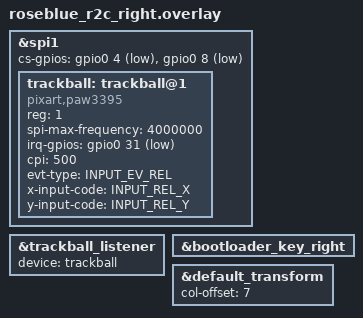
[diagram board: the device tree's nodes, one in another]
/* Right central with Skree's PAW3395 on the VIK connector. */
#include "roseblue_r2c.dtsi"
#include "../common/trackball-input.dtsi"

/* Chip select 0 remains the keyboard matrix's shift register. */
&spi1 {
    cs-gpios = <&gpio0 4 GPIO_ACTIVE_LOW>, <&gpio0 8 GPIO_ACTIVE_LOW>;

    trackball: trackball@1 {
        compatible = "pixart,paw3395";
        status = "okay";
        reg = <1>;
        spi-max-frequency = <4000000>;
        irq-gpios = <&gpio0 31 (GPIO_ACTIVE_LOW | GPIO_PULL_UP)>;
        cpi = <500>;
        evt-type = <INPUT_EV_REL>;
        x-input-code = <INPUT_REL_X>;
        y-input-code = <INPUT_REL_Y>;
    };
};

&trackball_listener {
    status = "okay";
    device = <&trackball>;
};

&bootloader_key_right {
    status = "okay";
};

&default_transform {
    col-offset = <7>;
};
